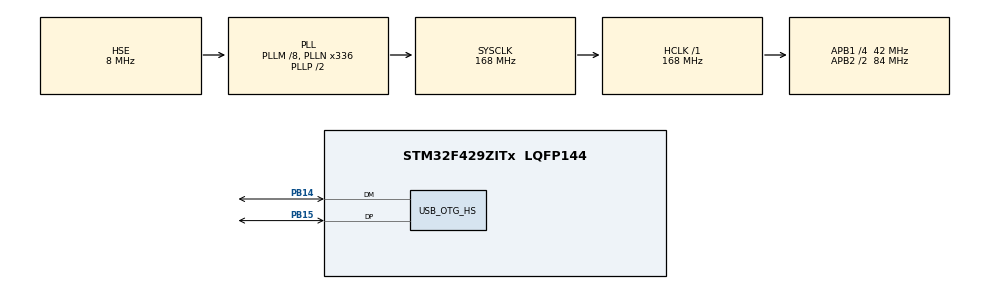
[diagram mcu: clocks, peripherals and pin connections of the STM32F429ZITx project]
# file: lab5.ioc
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Mcu.Family=STM32F4
Mcu.Name=STM32F429ZITx
Mcu.Package=LQFP144
NVIC.OTG_HS_IRQn=true\:0\:0\:false\:false\:true\:true\:true\:true
NVIC.PriorityGroup=NVIC_PRIORITYGROUP_4
PA13.Mode=Serial_Wire
PA13.Signal=SYS_JTMS-SWDIO
PA14.Mode=Serial_Wire
PA14.Signal=SYS_JTCK-SWCLK
PB14.Mode=Device_Only_FS
PB14.Signal=USB_OTG_HS_DM
PB15.Mode=Device_Only_FS
PB15.Signal=USB_OTG_HS_DP
PH0/OSC_IN.Mode=HSE-External-Oscillator
PH0/OSC_IN.Signal=RCC_OSC_IN
PH1/OSC_OUT.Mode=HSE-External-Oscillator
PH1/OSC_OUT.Signal=RCC_OSC_OUT
ProjectManager.HeapSize=0x2000
ProjectManager.StackSize=0x400
ProjectManager.TargetToolchain=STM32CubeIDE
RCC.48MHZClocksFreq_Value=48000000
RCC.AHBFreq_Value=168000000
RCC.APB1CLKDivider=RCC_HCLK_DIV4
RCC.APB1Freq_Value=42000000
RCC.APB1TimFreq_Value=84000000
RCC.APB2CLKDivider=RCC_HCLK_DIV2
RCC.APB2Freq_Value=84000000
RCC.APB2TimFreq_Value=168000000
RCC.CortexFreq_Value=168000000
RCC.HCLKFreq_Value=168000000
RCC.HSE_VALUE=8000000
RCC.HSI_VALUE=16000000
RCC.LSE_VALUE=32768
RCC.PLLM=8
RCC.PLLN=336
RCC.PLLQ=7
RCC.SYSCLKFreq_VALUE=168000000
RCC.SYSCLKSource=RCC_SYSCLKSOURCE_PLLCLK
RCC.VCOOutputFreq_Value=336000000
USB_DEVICE.CLASS_NAME_HS=CDC
USB_DEVICE.VirtualMode-CDC_HS=Cdc
USB_DEVICE.VirtualModeHS=Cdc_HS
USB_OTG_HS.VirtualMode-Device_Only_FS=Device_Only_FS
VP_USB_DEVICE_VS_USB_DEVICE_CDC_HS.Mode=CDC_HS
board=custom

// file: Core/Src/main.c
/* USER CODE BEGIN Header */
/**
  ******************************************************************************
  * @file           : main.c
  * @brief          : Main program body
  ******************************************************************************
  * @attention
  *
  * Copyright (c) 2024 STMicroelectronics.
  * All rights reserved.
  *
  * This software is licensed under terms that can be found in the LICENSE file
  * in the root directory of this software component.
  * If no LICENSE file comes with this software, it is provided AS-IS.
  *
  ******************************************************************************
  */
/* USER CODE END Header */
#include "main.h"
#include "usb_device.h"

/* USER CODE BEGIN Includes */
#include "stm32f429i_discovery_lcd.h"
#include "stm32f429i_discovery_sdram.h"
#include "stm32f429i_discovery_gyroscope.h"
#include "usbd_cdc_if.h"
/* USER CODE END Includes */

/* USER CODE BEGIN PD */
// Ngưỡng xác định nghiêng
#define THRESHOLD 500
/* USER CODE END PD */

/* USER CODE BEGIN PV */
int gameStarted = 0;
int isGameOver = 0;
int score = 0; // điểm số
int ball_r = 20; //bán kính bóng
int ball_hight = 20; // độ cao bóng
int step_hight = 2;
int step_r = 1;
uint8_t buffer_lcd[50];
uint8_t buffer_usb[50];
float data[3];

/* USER CODE END PV */

void SystemClock_Config(void);
static void MX_GPIO_Init(void);

int main(void)
{

  /* MCU Configuration--------------------------------------------------------*/

  /* Reset of all peripherals, Initializes the Flash interface and the Systick. */
  HAL_Init();

  /* Configure the system clock */
  SystemClock_Config();

  /* Initialize all configured peripherals */
  MX_GPIO_Init();
  MX_USB_DEVICE_Init();
  /* USER CODE BEGIN 2 */
  BSP_LCD_Init();//init LCD
  BSP_SDRAM_Init();
  BSP_GYRO_Init();

  //set the layer buffer address into SDRAM
  BSP_LCD_LayerDefaultInit(1, SDRAM_DEVICE_ADDR);
  BSP_LCD_SelectLayer(1);//select on which layer we write
  BSP_LCD_DisplayOn();//turn on LCD
  BSP_LCD_Clear(LCD_COLOR_WHITE);//clear the LCD on blue color
  BSP_LCD_SetBackColor(LCD_COLOR_WHITE);//set text background color
  BSP_LCD_SetTextColor(LCD_COLOR_BLUE);//set text color

  BSP_LCD_FillCircle(120, 160, ball_r);

  /* USER CODE END 2 */

  /* Infinite loop */
  while (1)
  {
	  sprintf(buffer_lcd, "Score: %d", score);
	  BSP_LCD_DisplayStringAtLine(1, buffer_lcd);

	  BSP_GYRO_GetXYZ(data);

	  if(!gameStarted){
		  if(data[1] > THRESHOLD){
			  gameStarted = 1;
		  }
		  continue;
	  }

	  // Xóa quả bóng trước đó
	  BSP_LCD_SetTextColor(LCD_COLOR_WHITE);
	  BSP_LCD_FillCircle(120, 160, ball_r);

	  ball_r += step_r; // Cập nhật bán kính
	  ball_hight += step_hight; // cập nhật độ cao

	  if (ball_r >= 60) {
		  step_r = -step_r;  // Đảo chiều
		  step_hight = -step_hight;
		  score++;
	  }

	  if (data[1] > THRESHOLD && ball_r < 60 && step_r < 0) {
		  step_r = -step_r;  // Đảo chiều
		  step_hight = -step_hight;
		  sprintf(buffer_usb, "Độ cao hiện tại là: %d", ball_hight);
		  CDC_Transmit_HS(buffer_usb, sizeof(buffer_usb));
	  }

	  if(ball_r <= 10){
		  isGameOver = 1;
	  }

	  if(isGameOver){
		  BSP_LCD_Clear(LCD_COLOR_RED);
		  BSP_LCD_SetBackColor(LCD_COLOR_RED);
		  BSP_LCD_SetTextColor(LCD_COLOR_WHITE);
		  BSP_LCD_DisplayStringAt(0, BSP_LCD_GetYSize()/2 - 10, "GAME OVER", CENTER_MODE);
		  BSP_LCD_DisplayStringAt(0, BSP_LCD_GetYSize()/2 + 10, buffer_lcd, CENTER_MODE);
		  score = 0;
		  break;
	  }

	  // Vẽ quả bóng mới
	  BSP_LCD_SetTextColor(LCD_COLOR_BLUE);
	  BSP_LCD_FillCircle(120, 160, ball_r);

	  HAL_Delay(30);
  }
}

void SystemClock_Config(void)
{
  RCC_OscInitTypeDef RCC_OscInitStruct = {0};
  RCC_ClkInitTypeDef RCC_ClkInitStruct = {0};

  /** Configure the main internal regulator output voltage
  */
  __HAL_RCC_PWR_CLK_ENABLE();
  __HAL_PWR_VOLTAGESCALING_CONFIG(PWR_REGULATOR_VOLTAGE_SCALE1);

  /** Initializes the RCC Oscillators according to the specified parameters
  * in the RCC_OscInitTypeDef structure.
  */
  RCC_OscInitStruct.OscillatorType = RCC_OSCILLATORTYPE_HSE;
  RCC_OscInitStruct.HSEState = RCC_HSE_ON;
  RCC_OscInitStruct.PLL.PLLState = RCC_PLL_ON;
  RCC_OscInitStruct.PLL.PLLSource = RCC_PLLSOURCE_HSE;
  RCC_OscInitStruct.PLL.PLLM = 8;
  RCC_OscInitStruct.PLL.PLLN = 336;
  RCC_OscInitStruct.PLL.PLLP = RCC_PLLP_DIV2;
  RCC_OscInitStruct.PLL.PLLQ = 7;
  if (HAL_RCC_OscConfig(&RCC_OscInitStruct) != HAL_OK)
  {
    Error_Handler();
  }

  /** Initializes the CPU, AHB and APB buses clocks
  */
  RCC_ClkInitStruct.ClockType = RCC_CLOCKTYPE_HCLK|RCC_CLOCKTYPE_SYSCLK
                              |RCC_CLOCKTYPE_PCLK1|RCC_CLOCKTYPE_PCLK2;
  RCC_ClkInitStruct.SYSCLKSource = RCC_SYSCLKSOURCE_PLLCLK;
  RCC_ClkInitStruct.AHBCLKDivider = RCC_SYSCLK_DIV1;
  RCC_ClkInitStruct.APB1CLKDivider = RCC_HCLK_DIV4;
  RCC_ClkInitStruct.APB2CLKDivider = RCC_HCLK_DIV2;

  if (HAL_RCC_ClockConfig(&RCC_ClkInitStruct, FLASH_LATENCY_5) != HAL_OK)
  {
    Error_Handler();
  }
}

static void MX_GPIO_Init(void)
{

  /* GPIO Ports Clock Enable */
  __HAL_RCC_GPIOH_CLK_ENABLE();
  __HAL_RCC_GPIOB_CLK_ENABLE();
  __HAL_RCC_GPIOA_CLK_ENABLE();

}

void Error_Handler(void)
{
  __disable_irq();
  while (1)
  {
  }
}
